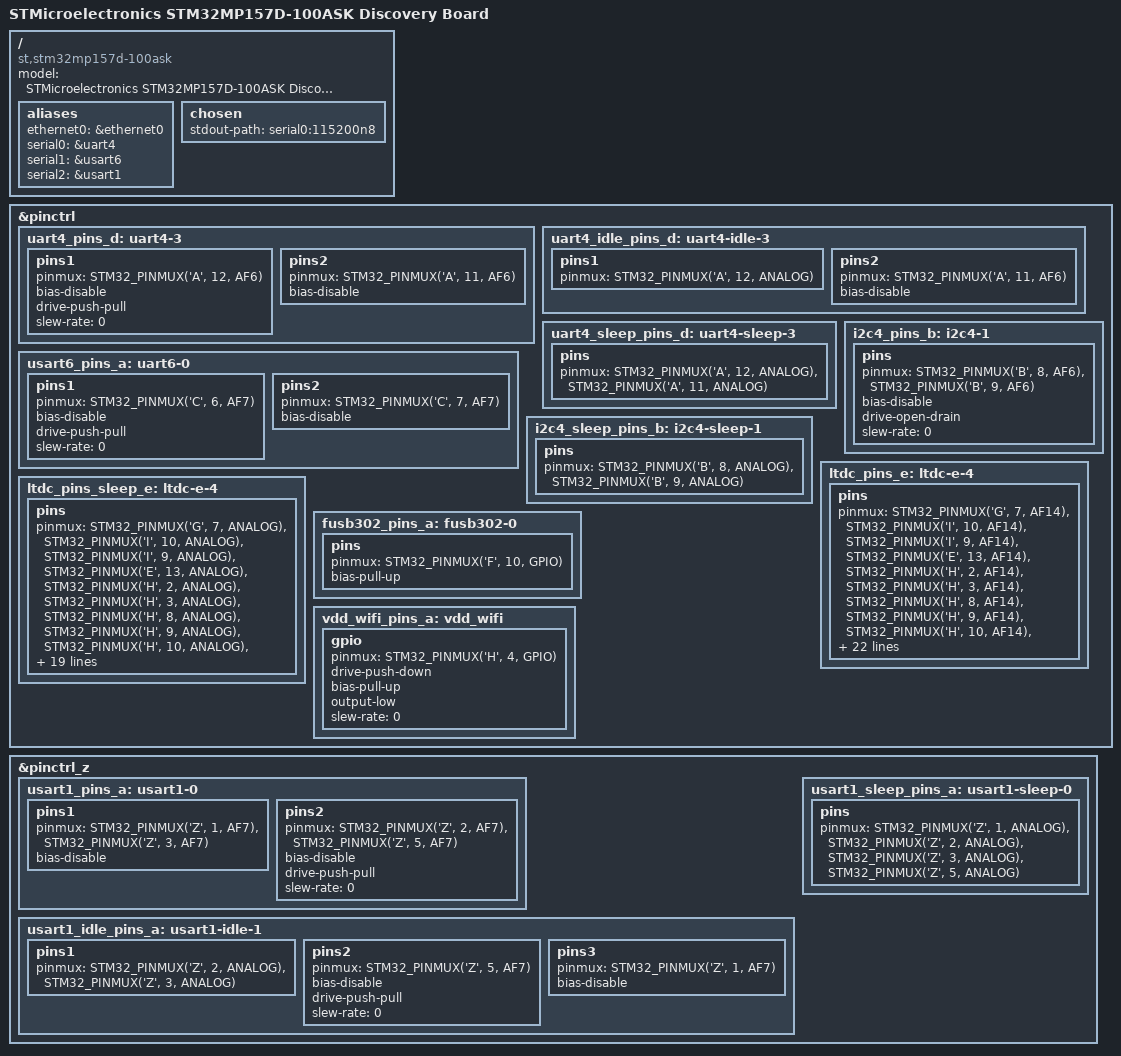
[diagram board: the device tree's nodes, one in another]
// SPDX-License-Identifier: (GPL-2.0+ OR BSD-3-Clause)
/*
 * Copyright (C) STMicroelectronics 2019 - All Rights Reserved
 * Author: Alexandre Torgue <alexandre.torgue@st.com> for STMicroelectronics.
 */

/dts-v1/;

#include "stm32mp157.dtsi"
#include "stm32mp15xd.dtsi"
#include "stm32mp15-pinctrl.dtsi"
#include "stm32mp15xxac-pinctrl.dtsi"
#include "stm32mp15xx-100ask.dtsi"

/ {
	model = "STMicroelectronics STM32MP157D-100ASK Discovery Board";
	compatible = "st,stm32mp157d-100ask", "st,stm32mp157";

	aliases {
		ethernet0 = &ethernet0;
		serial0 = &uart4;
		serial1 = &usart6;
		serial2 = &usart1;
	};

	chosen {
		stdout-path = "serial0:115200n8";
	};
};

&pinctrl {
	uart4_pins_d: uart4-3 {
		pins1 {
			pinmux = <STM32_PINMUX('A', 12, AF6)>; /* UART4_TX */
			bias-disable;
			drive-push-pull;
			slew-rate = <0>;
		};
		pins2 {
			pinmux = <STM32_PINMUX('A', 11, AF6)>; /* UART4_RX */
			bias-disable;
		};
	};

	uart4_idle_pins_d: uart4-idle-3 {
		pins1 {
			pinmux = <STM32_PINMUX('A', 12, ANALOG)>; /* UART4_TX */
		};
		pins2 {
			pinmux = <STM32_PINMUX('A', 11, AF6)>; /* UART4_RX */
			bias-disable;
		};
	};

	uart4_sleep_pins_d: uart4-sleep-3 {
		pins {
			pinmux = <STM32_PINMUX('A', 12, ANALOG)>, /* UART4_TX */
				<STM32_PINMUX('A', 11, ANALOG)>; /* UART4_RX */
		};
	};

	usart6_pins_a: uart6-0 {
		pins1 {
			pinmux = <STM32_PINMUX('C', 6, AF7)>; /* USART6_TX */
			bias-disable;
			drive-push-pull;
			slew-rate = <0>;
		};
		pins2 {
			pinmux = <STM32_PINMUX('C', 7, AF7)>; /* USART6_RX */
			bias-disable;
		};
	};

	i2c4_pins_b: i2c4-1 {
		pins {
			pinmux = <STM32_PINMUX('B', 8, AF6)>, /* I2C4_SCL */
				 <STM32_PINMUX('B', 9, AF6)>; /* I2C4_SDA */
			bias-disable;
			drive-open-drain;
			slew-rate = <0>;
		};
	};

	i2c4_sleep_pins_b: i2c4-sleep-1 {
		pins {
			pinmux = <STM32_PINMUX('B', 8, ANALOG)>, /* I2C4_SCL */
				 <STM32_PINMUX('B', 9, ANALOG)>; /* I2C4_SDA */
		};
	};

	ltdc_pins_e: ltdc-e-4 {
		pins {
			pinmux = <STM32_PINMUX('G',  7, AF14)>, /* LCD_CLK */
					<STM32_PINMUX('I', 10, AF14)>, /* LCD_HSYNC */
					<STM32_PINMUX('I',  9, AF14)>, /* LCD_VSYNC */
					<STM32_PINMUX('E', 13, AF14)>, /* LCD_DE */
					<STM32_PINMUX('H',  2, AF14)>, /* LCD_R0 */
					<STM32_PINMUX('H',  3, AF14)>, /* LCD_R1 */
					<STM32_PINMUX('H',  8, AF14)>, /* LCD_R2 */
					<STM32_PINMUX('H',  9, AF14)>, /* LCD_R3 */
					<STM32_PINMUX('H', 10, AF14)>, /* LCD_R4 */
					<STM32_PINMUX('H', 11, AF14)>, /* LCD_R5 */
					<STM32_PINMUX('H', 12, AF14)>, /* LCD_R6 */
					<STM32_PINMUX('E', 15, AF14)>, /* LCD_R7 */
					<STM32_PINMUX('E', 14, AF13)>, /* LCD_G0 */
					<STM32_PINMUX('E',  6, AF14)>, /* LCD_G1 */
					<STM32_PINMUX('H', 13, AF14)>, /* LCD_G2 */
					<STM32_PINMUX('H', 14, AF14)>, /* LCD_G3 */
					<STM32_PINMUX('H', 15, AF14)>, /* LCD_G4 */
					<STM32_PINMUX('I',  0, AF14)>, /* LCD_G5 */
					<STM32_PINMUX('I',  1, AF14)>, /* LCD_G6 */
					<STM32_PINMUX('I',  2, AF14)>, /* LCD_G7 */
					<STM32_PINMUX('D',  9, AF14)>, /* LCD_B0 */
					<STM32_PINMUX('G', 12, AF14)>, /* LCD_B1 */
					<STM32_PINMUX('G', 10, AF14)>, /* LCD_B2 */
					<STM32_PINMUX('D', 10, AF14)>, /* LCD_B3 */
					<STM32_PINMUX('I',  4, AF14)>, /* LCD_B4 */
					<STM32_PINMUX('I',  5, AF14)>, /* LCD_B5 */
					<STM32_PINMUX('I',  6, AF14)>, /* LCD_B6 */
					<STM32_PINMUX('I',  7, AF14)>; /* LCD_B7 */
			bias-disable;
			drive-push-pull;
			slew-rate = <1>;
		};
	};

	ltdc_pins_sleep_e: ltdc-e-4 {
		pins {
			pinmux = <STM32_PINMUX('G',  7, ANALOG)>, /* LCD_CLK */
					<STM32_PINMUX('I', 10, ANALOG)>, /* LCD_HSYNC */
					<STM32_PINMUX('I',  9, ANALOG)>, /* LCD_VSYNC */
					<STM32_PINMUX('E', 13, ANALOG)>, /* LCD_DE */
					<STM32_PINMUX('H',  2, ANALOG)>, /* LCD_R0 */
					<STM32_PINMUX('H',  3, ANALOG)>, /* LCD_R1 */
					<STM32_PINMUX('H',  8, ANALOG)>, /* LCD_R2 */
					<STM32_PINMUX('H',  9, ANALOG)>, /* LCD_R3 */
					<STM32_PINMUX('H', 10, ANALOG)>, /* LCD_R4 */
					<STM32_PINMUX('H', 11, ANALOG)>, /* LCD_R5 */
					<STM32_PINMUX('H', 12, ANALOG)>, /* LCD_R6 */
					<STM32_PINMUX('E', 15, ANALOG)>, /* LCD_R7 */
					<STM32_PINMUX('E', 14, ANALOG)>, /* LCD_G0 */
					<STM32_PINMUX('E',  6, ANALOG)>, /* LCD_G1 */
					<STM32_PINMUX('H', 13, ANALOG)>, /* LCD_G2 */
					<STM32_PINMUX('H', 14, ANALOG)>, /* LCD_G3 */
					<STM32_PINMUX('H', 15, ANALOG)>, /* LCD_G4 */
					<STM32_PINMUX('I',  0, ANALOG)>, /* LCD_G5 */
					<STM32_PINMUX('I',  1, ANALOG)>, /* LCD_G6 */
					<STM32_PINMUX('I',  2, ANALOG)>, /* LCD_G7 */
					<STM32_PINMUX('D',  9, ANALOG)>, /* LCD_B0 */
					<STM32_PINMUX('G', 12, ANALOG)>, /* LCD_B1 */
					<STM32_PINMUX('G', 10, ANALOG)>, /* LCD_B2 */
					<STM32_PINMUX('D', 10, ANALOG)>, /* LCD_B3 */
					<STM32_PINMUX('I',  4, ANALOG)>, /* LCD_B4 */
					<STM32_PINMUX('I',  5, ANALOG)>, /* LCD_B5 */
					<STM32_PINMUX('I',  6, ANALOG)>, /* LCD_B6 */
					<STM32_PINMUX('I',  7, ANALOG)>; /* LCD_B7 */
		};
	};

	fusb302_pins_a: fusb302-0 {
		pins {
			pinmux = <STM32_PINMUX('F', 10, GPIO)>;
			bias-pull-up;
		};
	};

	vdd_wifi_pins_a: vdd_wifi {
		gpio {
			pinmux = <STM32_PINMUX('H', 4, GPIO)>;
			drive-push-down;
			bias-pull-up;
			output-low;
			slew-rate = <0>;
		};
	};
};

&pinctrl_z {
	usart1_pins_a: usart1-0 {
		pins1 {
			pinmux = <STM32_PINMUX('Z', 1, AF7)>, /* USART1_RX */
					 <STM32_PINMUX('Z', 3, AF7)>; /* USART1_CTS */
			bias-disable;
		};
		pins2 {
			pinmux = <STM32_PINMUX('Z', 2, AF7)>, /* USART1_TX */
					 <STM32_PINMUX('Z', 5, AF7)>; /* USART1_RTS */
			bias-disable;
			drive-push-pull;
			slew-rate = <0>;
		};
	};

	usart1_idle_pins_a: usart1-idle-1 {
		pins1 {
			pinmux = <STM32_PINMUX('Z', 2, ANALOG)>, /* USART1_TX */
				 <STM32_PINMUX('Z', 3, ANALOG)>; /* USART1_CTS */
		};
		pins2 {
			pinmux = <STM32_PINMUX('Z', 5, AF7)>; /* USART1_RTS */
			bias-disable;
			drive-push-pull;
			slew-rate = <0>;
		};
		pins3 {
			pinmux = <STM32_PINMUX('Z', 1, AF7)>; /* USART1_RX */
			bias-disable;
		};
	};

	usart1_sleep_pins_a: usart1-sleep-0 {
		pins {
			pinmux = <STM32_PINMUX('Z', 1, ANALOG)>, /* USART1_RX */
					 <STM32_PINMUX('Z', 2, ANALOG)>, /* USART1_TX */
					 <STM32_PINMUX('Z', 3, ANALOG)>, /* USART1_CTS */
					 <STM32_PINMUX('Z', 5, ANALOG)>; /* USART1_RTS */
		};
	};
};
